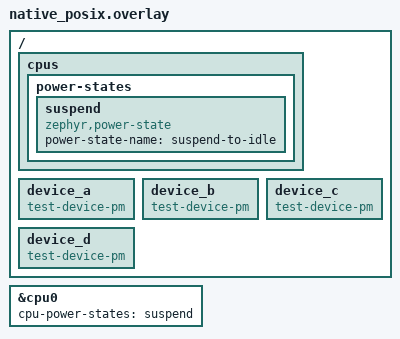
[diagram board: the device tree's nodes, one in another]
/*
 * Copyright (c) 2021 Intel Corporation.
 *
 * SPDX-License-Identifier: Apache-2.0
 */

/ {
	cpus {
		power-states {
			suspend: suspend {
				compatible = "zephyr,power-state";
				power-state-name = "suspend-to-idle";
			};
		};
	};

	device_a: device_a {
		compatible = "test-device-pm";
	};

	device_b: device_b {
		compatible = "test-device-pm";
	};

	device_c: device_c {
		compatible = "test-device-pm";
	};

	device_d: device_d {
		compatible = "test-device-pm";
	};
};

&cpu0 {
	cpu-power-states = <&suspend>;
};
